VERSION ""

NS_ :

BS_:

BU_:
VAL_TABLE_ BrkLiquidLevelValue_Tbl 1 "UNSUFFICIENT" 0 "SUFFICIENT" ;
VAL_TABLE_ TelltaleReq 3 "Not Available" 2 "Error" 1 "On" 0 "Off" ;

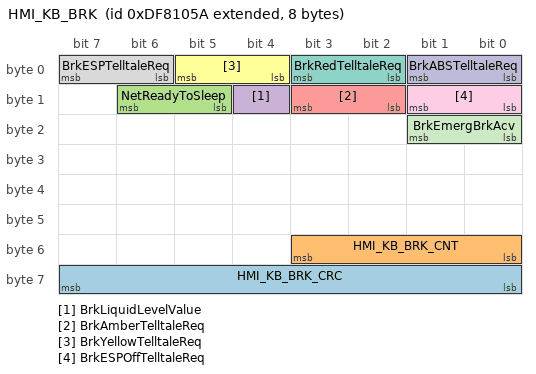
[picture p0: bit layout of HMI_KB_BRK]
BO_ 2381844570 HMI_KB_BRK: 8 Vector__XXX
 SG_ HMI_KB_BRK_CRC : 56|8@1+ (1,0) [0|255] "" Vector__XXX
 SG_ HMI_KB_BRK_CNT : 48|4@1+ (1,0) [0|15] "" Vector__XXX
 SG_ NetReadyToSleep : 13|2@1+ (1,0) [0|3] "" Vector__XXX
 SG_ BrkLiquidLevelValue : 12|1@1+ (1,0) [0|1] "" Vector__XXX
 SG_ BrkAmberTelltaleReq : 10|2@1+ (1,0) [0|0] "" Vector__XXX
 SG_ BrkYellowTelltaleReq : 4|2@1+ (1,0) [0|0] "" Vector__XXX
 SG_ BrkRedTelltaleReq : 2|2@1+ (1,0) [0|0] "" Vector__XXX
 SG_ BrkESPTelltaleReq : 6|2@1+ (1,0) [0|0] "" Vector__XXX
 SG_ BrkESPOffTelltaleReq : 8|2@1+ (1,0) [0|0] "" Vector__XXX
 SG_ BrkABSTelltaleReq : 0|2@1+ (1,0) [0|0] "" Vector__XXX
 SG_ BrkEmergBrkAcv : 16|2@1+ (1,0) [0|3] "" Vector__XXX

CM_ "Braking System Tell Tales Requests to HMI
 
$DBC storage: https://item.arrival.co/ui/repos/tree/General/dbc/  $
$Change: change_number $
$DateTime: YYYY/MM/DD HH:MM:SS $
$Revision: #revision_number $
$Author: zuev@arrival.com $";
CM_ BO_ 2381844570 "Braking signals
E2E protection: Autosar 1A
DATAID: 0x810";
CM_ SG_ 2381844570 BrkEmergBrkAcv "Emergency braking active flag";
CM_ SG_ 2381844570 HMI_KB_BRK_CRC "E2E CRC";
CM_ SG_ 2381844570 HMI_KB_BRK_CNT "E2E Counter";
CM_ SG_ 2381844570 NetReadyToSleep "True=Ready to sleep
False=Inhibit ready to sleep / switch-off of receiving system";
CM_ SG_ 2381844570 BrkAmberTelltaleReq "A 2 bit parameter to indicate the telltale indication request:
00b = Off
01b = On
10b = Error
11b = Not Available";
CM_ SG_ 2381844570 BrkRedTelltaleReq "A 2 bit parameter to indicate the telltale indication request:
00b = Off
01b = On
10b = Error
11b = Not Available";
BA_DEF_ SG_  "SigType" ENUM  "Default","Range","RangeSigned","ASCII","Discrete","Control","ReferencePGN","DTC","StringDelimiter","StringLength","StringLengthControl","MessageCounter","MessageChecksum";
BA_DEF_ SG_  "GenSigEVName" STRING ;
BA_DEF_ SG_  "GenSigILSupport" ENUM  "No","Yes";
BA_DEF_ SG_  "GenSigSendType" ENUM  "Cyclic","OnWrite","OnWriteWithRepetition","OnChange","OnChangeWithRepetition","IfActive","IfActiveWithRepetition","NoSigSendType";
BA_DEF_ SG_  "GenSigStartValue" INT 0 2147483647;
BA_DEF_ BO_  "GenMsgILSupport" ENUM  "No","Yes";
BA_DEF_ BU_  "NmStationAddress" INT 0 255;
BA_DEF_ BO_  "GenMsgSendType" ENUM  "cyclic","NotUsed","IfActive","NotUsed","NotUsed","NotUsed","NotUsed","NotUsed","noMsgSendType";
BA_DEF_ BO_  "SendOnChange" ENUM  "No","Yes";
BA_DEF_ BO_  "GenMsgRequestable" INT 0 1;
BA_DEF_ BO_  "GenMsgCycleTime" INT 0 3600000;
BA_DEF_  "DBName" STRING ;
BA_DEF_  "BusType" STRING ;
BA_DEF_  "ProtocolType" STRING ;
BA_DEF_ BO_  "VFrameFormat" ENUM  "StandardCAN","ExtendedCAN","reserved","J1939PG";
BA_DEF_DEF_  "SigType" "Default";
BA_DEF_DEF_  "GenSigEVName" "Env@Nodename_@Signame";
BA_DEF_DEF_  "GenSigILSupport" "Yes";
BA_DEF_DEF_  "GenSigSendType" "NoSigSendType";
BA_DEF_DEF_  "GenSigStartValue" 0;
BA_DEF_DEF_  "GenMsgILSupport" "Yes";
BA_DEF_DEF_  "NmStationAddress" 254;
BA_DEF_DEF_  "GenMsgSendType" "noMsgSendType";
BA_DEF_DEF_  "SendOnChange" "No";
BA_DEF_DEF_  "GenMsgRequestable" 1;
BA_DEF_DEF_  "GenMsgCycleTime" 0;
BA_DEF_DEF_  "DBName" "";
BA_DEF_DEF_  "BusType" "CAN";
BA_DEF_DEF_  "ProtocolType" "J1939";
BA_DEF_DEF_  "VFrameFormat" "J1939PG";
BA_ "DBName" "HMI_KB_BRK_DRV";
BA_ "GenMsgSendType" BO_ 2381844570 0;
BA_ "SendOnChange" BO_ 2381844570 1;
BA_ "GenMsgCycleTime" BO_ 2381844570 100;
BA_ "SigType" SG_ 2381844570 HMI_KB_BRK_CRC 12;
BA_ "SigType" SG_ 2381844570 HMI_KB_BRK_CNT 11;
BA_ "GenSigStartValue" SG_ 2381844570 BrkAmberTelltaleReq 3;
BA_ "GenSigStartValue" SG_ 2381844570 BrkYellowTelltaleReq 3;
BA_ "GenSigStartValue" SG_ 2381844570 BrkRedTelltaleReq 3;
BA_ "GenSigStartValue" SG_ 2381844570 BrkESPTelltaleReq 3;
BA_ "GenSigStartValue" SG_ 2381844570 BrkESPOffTelltaleReq 3;
BA_ "GenSigStartValue" SG_ 2381844570 BrkABSTelltaleReq 3;
VAL_ 2381844570 BrkEmergBrkAcv 3 "Not Available" 2 "Error" 1 "On" 0 "Off" ;
VAL_ 2381844570 NetReadyToSleep 3 "NA" 2 "Error" 0 "Inhibit Ready To Sleep" 1 "Ready To Sleep" ;
VAL_ 2381844570 BrkLiquidLevelValue 1 "UNSUFFICIENT" 0 "SUFFICIENT" ;
VAL_ 2381844570 BrkAmberTelltaleReq 3 "Not Available" 2 "Error" 1 "On" 0 "Off" ;
VAL_ 2381844570 BrkYellowTelltaleReq 3 "Not Available" 2 "Error" 1 "On" 0 "Off" ;
VAL_ 2381844570 BrkRedTelltaleReq 3 "Not Available" 2 "Error" 1 "On" 0 "Off" ;
VAL_ 2381844570 BrkESPTelltaleReq 3 "Not Available" 2 "Error" 1 "On" 0 "Off" ;
VAL_ 2381844570 BrkESPOffTelltaleReq 3 "Not Available" 2 "Error" 1 "On" 0 "Off" ;
VAL_ 2381844570 BrkABSTelltaleReq 3 "Not Available" 2 "Error" 1 "On" 0 "Off" ;
